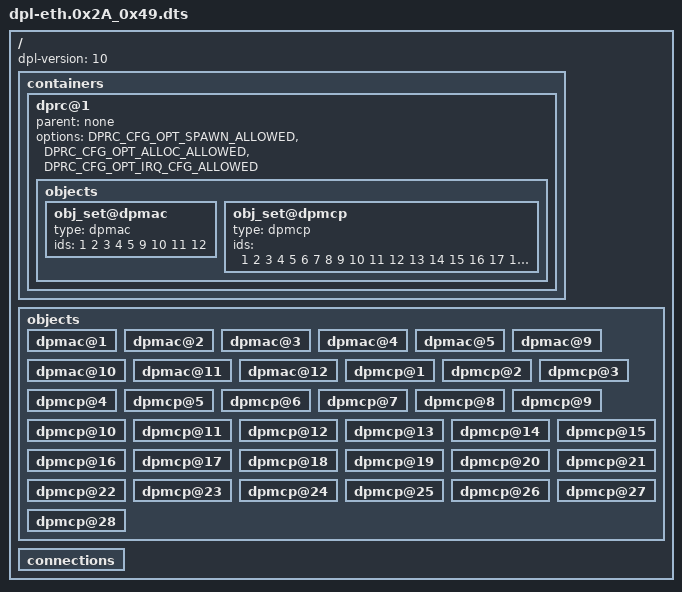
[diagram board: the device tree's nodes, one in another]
/*
 * Copyright 2016 Freescale Semiconductor, Inc.
 * Copyright 2017 NXP
 *
 * Redistribution and use in source and binary forms, with or without
 * modification, are permitted provided that the following conditions are met:
 *   * Redistributions of source code must retain the above copyright
 *     notice, this list of conditions and the following disclaimer.
 *   * Redistributions in binary form must reproduce the above copyright
 *     notice, this list of conditions and the following disclaimer in the
 *     documentation and/or other materials provided with the distribution.
 *   * Neither the name of the above-listed copyright holders nor the
 *     names of any contributors may be used to endorse or promote products
 *     derived from this software without specific prior written permission.
 *
 * THIS SOFTWARE IS PROVIDED BY THE COPYRIGHT HOLDERS AND CONTRIBUTORS "AS IS"
 * AND ANY EXPRESS OR IMPLIED WARRANTIES, INCLUDING, BUT NOT LIMITED TO, THE
 * IMPLIED WARRANTIES OF MERCHANTABILITY AND FITNESS FOR A PARTICULAR PURPOSE
 * ARE DISCLAIMED. IN NO EVENT SHALL THE COPYRIGHT HOLDERS OR CONTRIBUTORS BE
 * LIABLE FOR ANY DIRECT, INDIRECT, INCIDENTAL, SPECIAL, EXEMPLARY, OR
 * CONSEQUENTIAL DAMAGES (INCLUDING, BUT NOT LIMITED TO, PROCUREMENT OF
 * SUBSTITUTE GOODS OR SERVICES; LOSS OF USE, DATA, OR PROFITS; OR BUSINESS
 * INTERRUPTION) HOWEVER CAUSED AND ON ANY THEORY OF LIABILITY, WHETHER IN
 * CONTRACT, STRICT LIABILITY, OR TORT (INCLUDING NEGLIGENCE OR OTHERWISE)
 * ARISING IN ANY WAY OUT OF THE USE OF THIS SOFTWARE, EVEN IF ADVISED OF THE
 * POSSIBILITY OF SUCH DAMAGE.
 */

/*
 * This DPL showcases one basic Linux configuration for SerDes 0x2A_0x49.
 */

/dts-v1/;
/ {
	dpl-version = <10>;
	/*****************************************************************
         * Containers
         *****************************************************************/
	containers {
		dprc@1 {
			parent = "none";
			options = "DPRC_CFG_OPT_SPAWN_ALLOWED" , "DPRC_CFG_OPT_ALLOC_ALLOWED", "DPRC_CFG_OPT_IRQ_CFG_ALLOWED";

			objects {
				/* ------------- DPMACs --------------*/
				/* For SerDes 0x2a_49, 5 DPMACs are mapped
				 * on XFI ports and 4 DPMACs
				 * are mapped on the 4 SGMII ports of the PCIe
				 * Slot 4 riser card.
				 */
				obj_set@dpmac {
					type = "dpmac";
					ids = <1 2 3 4 5 9 10 11 12>;
				};

				/* ------------ DPMCPs --------------*/
				obj_set@dpmcp {
					type = "dpmcp";
					ids = <1 2 3 4 5 6 7 8 9 10 11 12 13 14 15 16 17 18 19 20 21 22 23 24 25 26 27 28>;
				};
			};
		};
	};

	/*****************************************************************
         * Objects
         *****************************************************************/
	objects {

		/* ------------ DPMAC --------------*/
		dpmac@1 {
		};
		dpmac@2 {
		};
		dpmac@3 {
		};
		dpmac@4 {
		};
		dpmac@5 {
		};

		dpmac@9 {
		};
		dpmac@10 {
		};
		dpmac@11 {
		};
		dpmac@12 {
		};

		/* ------------ DPMCP --------------*/
		dpmcp@1 {
		};
		dpmcp@2 {
		};
		dpmcp@3 {
		};
		dpmcp@4 {
		};
		dpmcp@5 {
		};
		dpmcp@6 {
		};
		dpmcp@7 {
		};
		dpmcp@8 {
		};
		dpmcp@9 {
		};
		dpmcp@10 {
		};
		dpmcp@11 {
		};
		dpmcp@12 {
		};
		dpmcp@13 {
		};
		dpmcp@14 {
		};
		dpmcp@15 {
		};
		dpmcp@16 {
		};
		dpmcp@17 {
		};
		dpmcp@18 {
		};
		dpmcp@19 {
		};
		dpmcp@20 {
		};
		dpmcp@21 {
		};
		dpmcp@22 {
		};
		dpmcp@23 {
		};
		dpmcp@24 {
		};
		dpmcp@25 {
		};
		dpmcp@26 {
		};
		dpmcp@27 {
		};
		dpmcp@28 {
		};
	};

	/*****************************************************************
         * Connections
         *****************************************************************/
	connections {
	};
};
